VERSION ""

NS_ :

BS_:

BU_: EPS VSA EON INTERCEPTOR

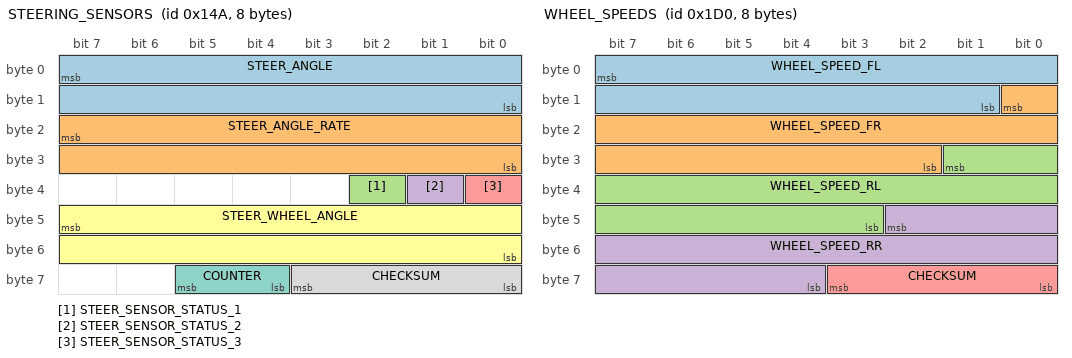
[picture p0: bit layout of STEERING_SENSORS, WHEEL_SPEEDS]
BO_ 330 STEERING_SENSORS: 8 EPS
 SG_ STEER_ANGLE : 7|16@0- (-0.1,0) [-500|500] "deg" EON
 SG_ STEER_ANGLE_RATE : 23|16@0- (-1,0) [-3000|3000] "deg/s" EON
 SG_ STEER_SENSOR_STATUS_1 : 34|1@0+ (1,0) [0|1] "" EON
 SG_ STEER_SENSOR_STATUS_2 : 33|1@0+ (1,0) [0|1] "" EON
 SG_ STEER_SENSOR_STATUS_3 : 32|1@0+ (1,0) [0|1] "" EON
 SG_ STEER_WHEEL_ANGLE : 47|16@0- (-0.1,0) [-500|500] "deg" EON
 SG_ COUNTER : 61|2@0+ (1,0) [0|3] "" EON
 SG_ CHECKSUM : 59|4@0+ (1,0) [0|3] "" EON

BO_ 464 WHEEL_SPEEDS: 8 VSA
 SG_ WHEEL_SPEED_FL : 7|15@0+ (0.01,0) [0|250] "kph" EON
 SG_ WHEEL_SPEED_FR : 8|15@0+ (0.01,0) [0|250] "kph" EON
 SG_ WHEEL_SPEED_RL : 25|15@0+ (0.01,0) [0|250] "kph" EON
 SG_ WHEEL_SPEED_RR : 42|15@0+ (0.01,0) [0|250] "kph" EON
 SG_ CHECKSUM : 59|4@0+ (1,0) [0|3] "" EON

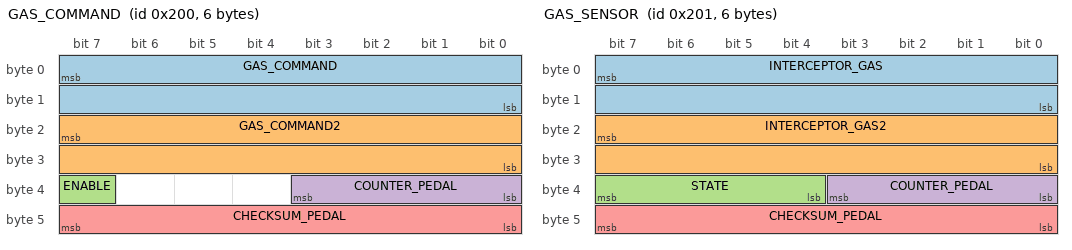
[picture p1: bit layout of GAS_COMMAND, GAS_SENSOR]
BO_ 512 GAS_COMMAND: 6 EON
 SG_ GAS_COMMAND : 7|16@0+ (0.253984064,-83.3) [0|1] "" INTERCEPTOR
 SG_ GAS_COMMAND2 : 23|16@0+ (0.126992032,-83.3) [0|1] "" INTERCEPTOR
 SG_ ENABLE : 39|1@0+ (1,0) [0|1] "" INTERCEPTOR
 SG_ COUNTER_PEDAL : 35|4@0+ (1,0) [0|15] "" INTERCEPTOR
 SG_ CHECKSUM_PEDAL : 47|8@0+ (1,0) [0|255] "" INTERCEPTOR

BO_ 513 GAS_SENSOR: 6 INTERCEPTOR
 SG_ INTERCEPTOR_GAS : 7|16@0+ (0.25,-65.5) [0|1] "" EON
 SG_ INTERCEPTOR_GAS2 : 23|16@0+ (0.75,-25.5) [0|1] "" EON
 SG_ STATE : 39|4@0+ (1,0) [0|15] "" EON
 SG_ COUNTER_PEDAL : 35|4@0+ (1,0) [0|15] "" EON
 SG_ CHECKSUM_PEDAL : 47|8@0+ (1,0) [0|255] "" EON
